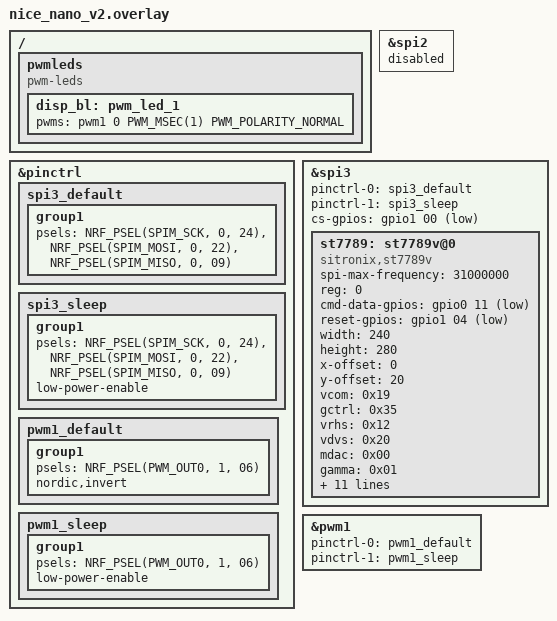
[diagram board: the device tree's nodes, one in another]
/ {
   pwmleds 
   {
      compatible = "pwm-leds";
      disp_bl: pwm_led_1 
      {
         pwms = <&pwm1 0 PWM_MSEC(1) PWM_POLARITY_NORMAL>;
      };
  };
};

&spi2 {status = "disabled";};
// vcc
// gnd
// DIN 0 22
// CLK 0 24 done
// CS  1 00 done
// DC  0 11 done
// RST 1 04 done
// BL  1 06 done

&pinctrl 
{
   spi3_default: spi3_default 
   {
		group1 
      {
			psels = <NRF_PSEL(SPIM_SCK,  0, 24)>, //SCL
				     <NRF_PSEL(SPIM_MOSI, 0, 22)>, //SDA
				     <NRF_PSEL(SPIM_MISO, 0, 09)>; // 0 09
		};
	};

	spi3_sleep: spi3_sleep 
   {
		group1 
      {
			psels = <NRF_PSEL(SPIM_SCK,  0, 24)>,
				     <NRF_PSEL(SPIM_MOSI, 0, 22)>,
				     <NRF_PSEL(SPIM_MISO, 0, 09)>;
			low-power-enable;
		};
	};

   pwm1_default: pwm1_default 
   {
      group1 
      {
         psels = <NRF_PSEL(PWM_OUT0, 1, 06)>;
         nordic,invert;
      };
   };

   pwm1_sleep: pwm1_sleep 
   {
      group1 
      {
         psels = <NRF_PSEL(PWM_OUT0, 1, 06)>;
         low-power-enable;
      };
   };
};

disp_spi: &spi3 
{
   status = "okay";
   pinctrl-0 = <&spi3_default>;
	pinctrl-1 = <&spi3_sleep>;
	pinctrl-names = "default", "sleep";
   cs-gpios = <&gpio1 00 GPIO_ACTIVE_LOW>; //CS

   st7789: st7789v@0 
   {
      compatible = "sitronix,st7789v";
      spi-max-frequency = <31000000>;
      reg = <0>;
      cmd-data-gpios = <&gpio0 11 GPIO_ACTIVE_LOW>; //DC
      reset-gpios = <&gpio1 04 GPIO_ACTIVE_LOW>; // RES
      width = <240>;
      height = <280>;
      x-offset = <0>;
      y-offset = <20>;
      vcom = <0x19>;
      gctrl = <0x35>;
      vrhs = <0x12>;
      vdvs = <0x20>;
      mdac = <0x00>;
      gamma = <0x01>;
      colmod = <0x05>;
      lcm = <0x2c>;
      porch-param = [ 0c 0c 00 33 33  ];
      cmd2en-param = [ 5a 69 02 01  ];
      pwctrl1-param = [ a4 a1  ];
      pvgam-param = [ D0 04 0D 11 13 2B 3F 54 4C 18 0D 0B 1F 23  ];
      nvgam-param = [ D0 04 0C 11 13 2C 3F 44 51 2F 1F 1F 20 23  ];
      ram-param = [ 00 F0  ];
      rgb-param = [ CD 08 14  ];
   };
};

&pwm1 
{
  status = "okay";
  pinctrl-0 = <&pwm1_default>;
  pinctrl-1 = <&pwm1_sleep>;
  pinctrl-names = "default", "sleep";
};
